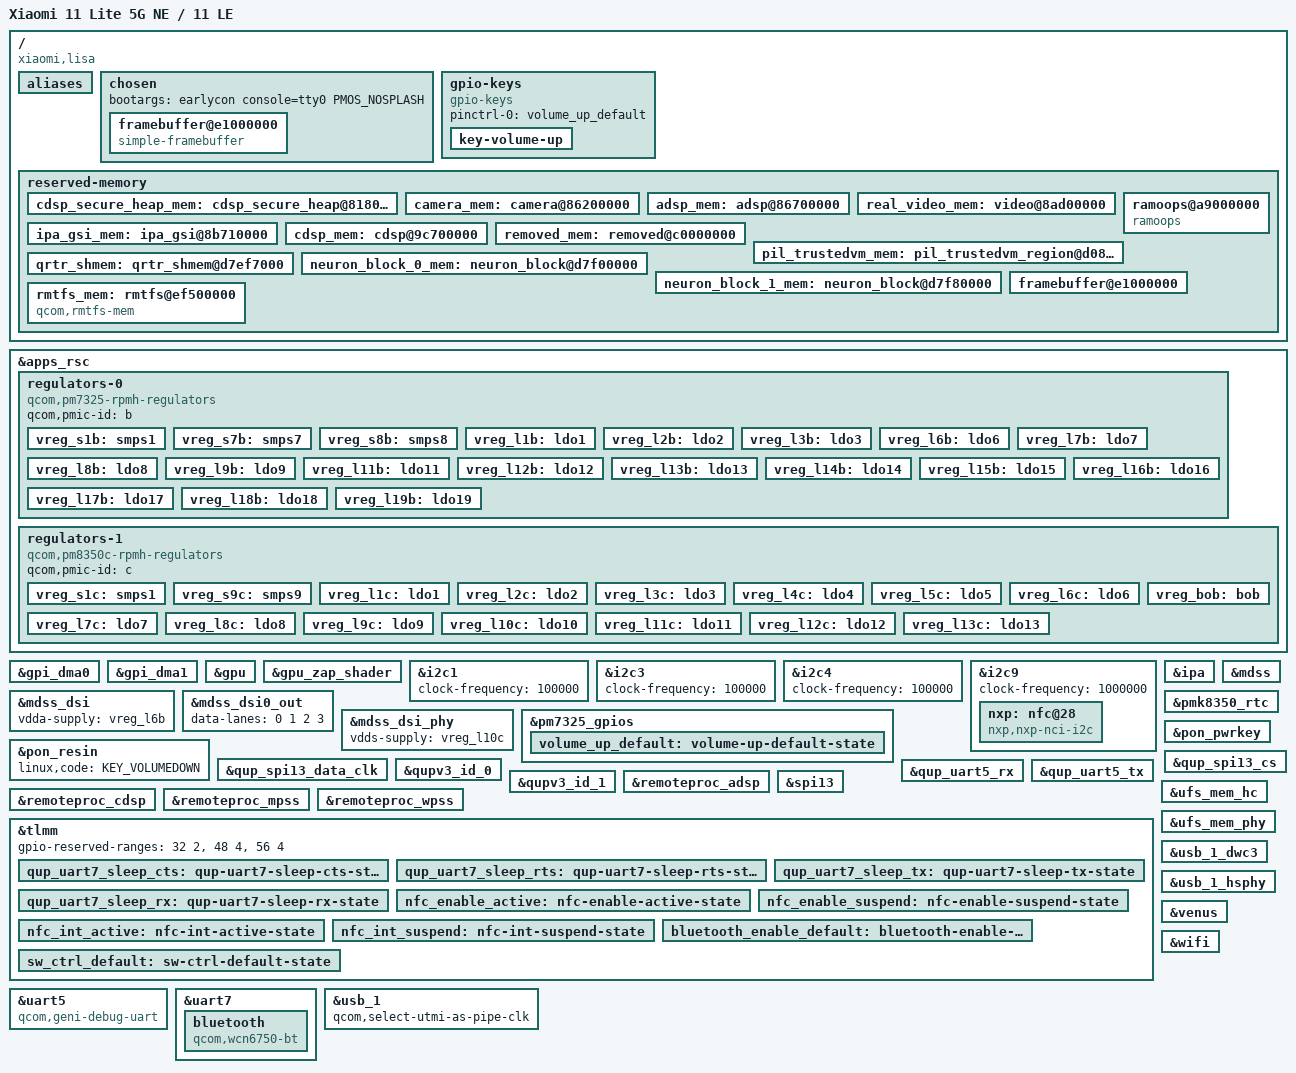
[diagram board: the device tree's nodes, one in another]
// SPDX-License-Identifier: BSD-3-Clause
/*
 * Copyright (c) 2024, Jens Reidel <adrian@travitia.xyz>
 */

/dts-v1/;

#include <dt-bindings/gpio/gpio.h>
#include <dt-bindings/regulator/qcom,rpmh-regulator.h>
#include <dt-bindings/leds/common.h>

#include <dt-bindings/pinctrl/qcom,pmic-gpio.h>
#include "sm7325.dtsi"
#include "pm7325.dtsi"
#include "pm8350b.dtsi" /* PM7325B */
#include "pm8350c.dtsi" /* PM7350C */
#include "pmk8350.dtsi" /* PMK7325 */
#include "pmr735a.dtsi"
/*
 * pmk8350 @ 0
 * pm7325  @ 1
 * pm8350c @ 2
 * pm8350b @ 3
 * pmr735a @ 4
 */

/* The following reserved memory regions have different addresses or sizes */
/delete-node/ &adsp_mem;
/delete-node/ &cdsp_mem;
/delete-node/ &rmtfs_mem;

/ {
	model = "Xiaomi 11 Lite 5G NE / 11 LE";
	compatible = "xiaomi,lisa", "qcom,sm7325";
	qcom,msm-id = <475 0x10000>;
	qcom,board-id = <0x1000b 0x00>;
	chassis-type = "handset";

	aliases {
		serial0 = &uart5;
		serial1 = &uart7;
	};

	chosen {
		#address-cells = <2>;
		#size-cells = <2>;
		ranges;

		//stdout-path = "serial0:115200n8";
		bootargs = "earlycon console=tty0 PMOS_NOSPLASH";

		framebuffer@e1000000 {
			compatible = "simple-framebuffer";
			reg = <0x0 0xe1000000 0x0 (1080 * 2400 * 4)>;
			width = <1080>;
			height = <2400>;
			stride = <(1080 * 4)>;
			format = "a8r8g8b8";
		};
	};

	gpio-keys {
		compatible = "gpio-keys";

		pinctrl-0 = <&volume_up_default>;
		pinctrl-names = "default";

		key-volume-up {
			label = "Volume up";
			gpios = <&pm7325_gpios 6 GPIO_ACTIVE_LOW>;
			linux,code = <KEY_VOLUMEUP>;
		};
	};

	/*
	pmic-glink {
		compatible = "qcom,sm7325-pmic-glink",
			     "qcom,pmic-glink";

		#address-cells = <1>;
		#size-cells = <0>;

		connector@0 {
			compatible = "usb-c-connector";
			reg = <0>;
			power-role = "dual";
			data-role = "dual";

			ports {
				#address-cells = <1>;
				#size-cells = <0>;

				port@0 {
					reg = <0>;

					pmic_glink_hs_in: endpoint {
						remote-endpoint = <&usb_1_dwc3_hs>;
					};
				};

				port@1 {
					reg = <1>;

					pmic_glink_sbu: endpoint {
						remote-endpoint = <&fsa4480_sbu_mux>;
					};
				};
			};
		};
	};
	*/

	reserved-memory {
		#address-cells = <2>;
		#size-cells = <2>;
		ranges;

		cdsp_secure_heap_mem: cdsp_secure_heap@81800000 {
			reg = <0x0 0x81800000 0x0 0x1e00000>;
			no-map;
		};

		camera_mem: camera@86200000 {
			reg = <0x0 0x86200000 0x0 0x500000>;
			no-map;
		};

		adsp_mem: adsp@86700000 {
			reg = <0x0 0x86700000 0x0 0x4000000>;
			no-map;
		};

		/* Mainline video_mem is downstream cvp_mem */
		real_video_mem: video@8ad00000 {
			reg = <0x0 0x8ad00000 0x0 0x500000>;
			no-map;
		};

		ipa_gsi_mem: ipa_gsi@8b710000 {
			reg = <0x0 0x8b710000 0x0 0xa000>;
			no-map;
		};

		cdsp_mem: cdsp@9c700000 {
			reg = <0x0 0x9c700000 0x0 0x1e00000>;
			no-map;
		};

		ramoops@a9000000 {
			compatible = "ramoops";
			reg = <0x0 0xa9000000 0x0 0x200000>;
			pmsg-size = <0x200000>;
			mem-type = <0x02>;
		};

		removed_mem: removed@c0000000 {
			reg = <0x0 0xc0000000 0x0 0x5100000>;
			no-map;
		};

		pil_trustedvm_mem: pil_trustedvm_region@d0800000 {
			reg = <0x0 0xd0800000 0x0 0x76f7000>;
			no-map;
		};

		qrtr_shmem: qrtr_shmem@d7ef7000 {
			reg = <0x0 0xd7ef7000 0x0 0x9000>;
			no-map;
		};

		neuron_block_0_mem: neuron_block@d7f00000 {
			reg = <0x0 0xd7f00000 0x0 0x80000>;
			no-map;
		};

		neuron_block_1_mem: neuron_block@d7f80000 {
			reg = <0x0 0xd7f80000 0x0 0x80000>;
			no-map;
		};

		framebuffer@e1000000 {
			reg = <0x0 0xe1000000 0x0 (1080 * 2400 * 4)>;
			no-map;
		};

		rmtfs_mem: rmtfs@ef500000 {
			compatible = "qcom,rmtfs-mem";
			reg = <0x0 0xef500000 0x0 0x280000>;
			no-map;

			qcom,client-id = <1>;
			qcom,vmid = <QCOM_SCM_VMID_MSS_MSA>,
				    <QCOM_SCM_VMID_NAV>;
		};
	};

	/*
	thermal-zones {
		camera-thermal {
			polling-delay-passive = <0>;
			polling-delay = <0>;
			thermal-sensors = <&pmk8350_adc_tm 2>;

			trips {
				active-config0 {
					temperature = <125000>;
					hysteresis = <1000>;
					type = "passive";
				};
			};
		};

		chg-skin-thermal {
			polling-delay-passive = <0>;
			polling-delay = <0>;
			thermal-sensors = <&pmk8350_adc_tm 6>;

			trips {
				active-config0 {
					temperature = <125000>;
					hysteresis = <1000>;
					type = "passive";
				};
			};
		};

		conn-thermal {
			polling-delay-passive = <0>;
			polling-delay = <0>;
			thermal-sensors = <&pmk8350_adc_tm 5>;

			trips {
				active-config0 {
					temperature = <125000>;
					hysteresis = <1000>;
					type = "passive";
				};
			};
		};

		quiet-thermal {
			polling-delay-passive = <0>;
			polling-delay = <0>;
			thermal-sensors = <&pmk8350_adc_tm 1>;

			trips {
				active-config0 {
					temperature = <125000>;
					hysteresis = <1000>;
					type = "passive";
				};
			};
		};

		rear-cam-thermal {
			polling-delay-passive = <0>;
			polling-delay = <0>;
			thermal-sensors = <&pmk8350_adc_tm 4>;

			trips {
				active-config0 {
					temperature = <125000>;
					hysteresis = <1000>;
					type = "passive";
				};
			};
		};

		sdm-skin-thermal {
			polling-delay-passive = <0>;
			polling-delay = <0>;
			thermal-sensors = <&pmk8350_adc_tm 3>;

			trips {
				active-config0 {
					temperature = <125000>;
					hysteresis = <1000>;
					type = "passive";
				};
			};
		};

		xo-thermal {
			polling-delay-passive = <0>;
			polling-delay = <0>;
			thermal-sensors = <&pmk8350_adc_tm 0>;

			trips {
				active-config0 {
					temperature = <125000>;
					hysteresis = <1000>;
					type = "passive";
				};
			};
		};
	};
	*/
};

&apps_rsc {
	regulators-0 {
		compatible = "qcom,pm7325-rpmh-regulators";
		qcom,pmic-id = "b";

		vreg_s1b: smps1 {
			regulator-min-microvolt = <1840000>;
			regulator-max-microvolt = <2040000>;
		};

		vreg_s7b: smps7 {
			regulator-min-microvolt = <535000>;
			regulator-max-microvolt = <1120000>;
		};

		vreg_s8b: smps8 {
			regulator-min-microvolt = <1200000>;
			regulator-max-microvolt = <1500000>;
			regulator-initial-mode = <RPMH_REGULATOR_MODE_RET>;
		};

		vreg_l1b: ldo1 {
			regulator-min-microvolt = <825000>;
			regulator-max-microvolt = <925000>;
			regulator-initial-mode = <RPMH_REGULATOR_MODE_HPM>;
		};

		vreg_l2b: ldo2 {
			regulator-min-microvolt = <2700000>;
			regulator-max-microvolt = <3544000>;
			regulator-initial-mode = <RPMH_REGULATOR_MODE_HPM>;
		};

		vreg_l3b: ldo3 {
			regulator-min-microvolt = <312000>;
			regulator-max-microvolt = <910000>;
			regulator-initial-mode = <RPMH_REGULATOR_MODE_HPM>;
		};

		vreg_l6b: ldo6 {
			regulator-min-microvolt = <1140000>;
			regulator-max-microvolt = <1260000>;
			regulator-initial-mode = <RPMH_REGULATOR_MODE_HPM>;
			regulator-allow-set-load;
			regulator-allowed-modes = <RPMH_REGULATOR_MODE_LPM
						   RPMH_REGULATOR_MODE_HPM>;
		};

		vreg_l7b: ldo7 {
			regulator-min-microvolt = <2400000>;
			regulator-max-microvolt = <3544000>;
			regulator-initial-mode = <RPMH_REGULATOR_MODE_HPM>;
			regulator-allow-set-load;
			regulator-allowed-modes = <RPMH_REGULATOR_MODE_LPM
						   RPMH_REGULATOR_MODE_HPM>;
		};

		vreg_l8b: ldo8 {
			regulator-min-microvolt = <870000>;
			regulator-max-microvolt = <970000>;
			regulator-initial-mode = <RPMH_REGULATOR_MODE_HPM>;
		};

		vreg_l9b: ldo9 {
			regulator-min-microvolt = <1200000>;
			regulator-max-microvolt = <1304000>;
			regulator-initial-mode = <RPMH_REGULATOR_MODE_HPM>;
			regulator-allow-set-load;
			regulator-allowed-modes = <RPMH_REGULATOR_MODE_LPM
						   RPMH_REGULATOR_MODE_HPM>;
		};

		vreg_l11b: ldo11 {
			regulator-min-microvolt = <1504000>;
			regulator-max-microvolt = <2000000>;
			regulator-initial-mode = <RPMH_REGULATOR_MODE_HPM>;
		};

		vreg_l12b: ldo12 {
			regulator-min-microvolt = <751000>;
			regulator-max-microvolt = <824000>;
			regulator-initial-mode = <RPMH_REGULATOR_MODE_HPM>;
		};

		vreg_l13b: ldo13 {
			regulator-min-microvolt = <530000>;
			regulator-max-microvolt = <824000>;
			regulator-initial-mode = <RPMH_REGULATOR_MODE_HPM>;
		};

		vreg_l14b: ldo14 {
			regulator-min-microvolt = <1080000>;
			regulator-max-microvolt = <1304000>;
			regulator-initial-mode = <RPMH_REGULATOR_MODE_HPM>;
		};

		vreg_l15b: ldo15 {
			regulator-min-microvolt = <765000>;
			regulator-max-microvolt = <1020000>;
			regulator-initial-mode = <RPMH_REGULATOR_MODE_HPM>;
		};

		vreg_l16b: ldo16 {
			regulator-min-microvolt = <1100000>;
			regulator-max-microvolt = <1300000>;
			regulator-initial-mode = <RPMH_REGULATOR_MODE_HPM>;
		};

		vreg_l17b: ldo17 {
			regulator-min-microvolt = <1700000>;
			regulator-max-microvolt = <1900000>;
			regulator-initial-mode = <RPMH_REGULATOR_MODE_HPM>;
		};

		vreg_l18b: ldo18 {
			regulator-min-microvolt = <1800000>;
			regulator-max-microvolt = <2000000>;
			regulator-initial-mode = <RPMH_REGULATOR_MODE_HPM>;
		};

		vreg_l19b: ldo19 {
			regulator-min-microvolt = <1800000>;
			regulator-max-microvolt = <2000000>;
			regulator-initial-mode = <RPMH_REGULATOR_MODE_HPM>;
		};
	};

	regulators-1 {
		compatible = "qcom,pm8350c-rpmh-regulators";
		qcom,pmic-id = "c";

		vreg_s1c: smps1 {
			regulator-min-microvolt = <2190000>;
			regulator-max-microvolt = <2210000>;
		};

		vreg_s9c: smps9 {
			regulator-min-microvolt = <1010000>;
			regulator-max-microvolt = <1170000>;
		};

		vreg_l1c: ldo1 {
			regulator-min-microvolt = <1800000>;
			regulator-max-microvolt = <1980000>;
			regulator-initial-mode = <RPMH_REGULATOR_MODE_HPM>;
		};

		vreg_l2c: ldo2 {
			regulator-min-microvolt = <1620000>;
			regulator-max-microvolt = <1980000>;
			regulator-initial-mode = <RPMH_REGULATOR_MODE_HPM>;
		};

		vreg_l3c: ldo3 {
			regulator-min-microvolt = <3300000>;
			regulator-max-microvolt = <3300000>;
			regulator-initial-mode = <RPMH_REGULATOR_MODE_HPM>;
			regulator-always-on;
		};

		vreg_l4c: ldo4 {
			regulator-min-microvolt = <1620000>;
			regulator-max-microvolt = <3300000>;
			regulator-initial-mode = <RPMH_REGULATOR_MODE_HPM>;
		};

		vreg_l5c: ldo5 {
			regulator-min-microvolt = <1620000>;
			regulator-max-microvolt = <3300000>;
			regulator-initial-mode = <RPMH_REGULATOR_MODE_HPM>;
		};

		vreg_l6c: ldo6 {
			regulator-min-microvolt = <1650000>;
			regulator-max-microvolt = <3544000>;
			regulator-initial-mode = <RPMH_REGULATOR_MODE_HPM>;
		};

		vreg_l7c: ldo7 {
			regulator-min-microvolt = <3000000>;
			regulator-max-microvolt = <3544000>;
			regulator-initial-mode = <RPMH_REGULATOR_MODE_HPM>;
		};

		vreg_l8c: ldo8 {
			regulator-min-microvolt = <1620000>;
			regulator-max-microvolt = <2000000>;
			regulator-initial-mode = <RPMH_REGULATOR_MODE_HPM>;
			regulator-always-on;
		};

		vreg_l9c: ldo9 {
			regulator-min-microvolt = <2700000>;
			regulator-max-microvolt = <3544000>;
			regulator-initial-mode = <RPMH_REGULATOR_MODE_HPM>;
		};

		vreg_l10c: ldo10 {
			regulator-min-microvolt = <720000>;
			regulator-max-microvolt = <1050000>;
			regulator-initial-mode = <RPMH_REGULATOR_MODE_HPM>;
			regulator-allow-set-load;
			regulator-allowed-modes = <RPMH_REGULATOR_MODE_LPM
						   RPMH_REGULATOR_MODE_HPM>;
		};

		vreg_l11c: ldo11 {
			regulator-min-microvolt = <2800000>;
			regulator-max-microvolt = <3544000>;
			regulator-initial-mode = <RPMH_REGULATOR_MODE_HPM>;
		};

		vreg_l12c: ldo12 {
			regulator-min-microvolt = <1650000>;
			regulator-max-microvolt = <2000000>;
			regulator-initial-mode = <RPMH_REGULATOR_MODE_HPM>;
		};

		vreg_l13c: ldo13 {
			regulator-min-microvolt = <2700000>;
			regulator-max-microvolt = <3544000>;
			regulator-initial-mode = <RPMH_REGULATOR_MODE_HPM>;
		};

		vreg_bob: bob {
			regulator-min-microvolt = <3008000>;
			regulator-max-microvolt = <3960000>;
			regulator-initial-mode = <RPMH_REGULATOR_MODE_AUTO>;
		};
	};
};

/*
&cci0 {
	status = "okay";
};

&cci1 {
	status = "okay";
};
*/

&gpi_dma0 {
	status = "okay";
};

&gpi_dma1 {
	status = "okay";
};

&gpu {
	status = "okay";
};

&gpu_zap_shader {
	firmware-name = "qcom/sm7325/xiaomi/lisa/a660_zap.mbn";
};

&i2c1 {
	clock-frequency = <100000>;
	status = "okay";

	/*
	 * Downstream DTS has 4 pm8008X pmics, but i2cdetect
	 * doesnt see any devices at these addresses
	 *
	 * #include "pm8008.dtsi"
	 *
         * pm8008i qcom,i2c-pmic @ 8
	 * pm8008i qcom,i2c-pmic @ 9
	 * pm8008j qcom,i2c-pmic @ c
	 * pm8008j qcom,i2c-pmic @ d
	 *
	 */

	/* awinic,aw210xx_led @ 20 */

	/* TODO: It has this but supply?
	fsa4480: switcher@42 {
		compatible = "fcs,fsa4480";
		reg = <0x42>;

		vcc-supply = <&vreg_bob>;

		mode-switch;
		orientation-switch;

		port {
			fsa4480_sbu_mux: endpoint {
				remote-endpoint = <&pmic_glink_sbu>;
			};
		};
	};
	*/

	/*
	 * I guess this is also not used:
	 *
	 * nq rtc6226 @ 64
	 */
};

&i2c3 {
	clock-frequency = <100000>;
	status = "okay";

	/* tfa,tfa98xx @ 34 */
	/* tfa,tfa98xx @ 35 */
};

&i2c4 {
	clock-frequency = <100000>;
	status = "okay";

	/* awinic,aw8624_haptic @ 5a */
};

&i2c9 {
	clock-frequency = <1000000>;
	status = "okay";

	nxp: nfc@28 {
		compatible = "nxp,nxp-nci-i2c";
		reg = <0x28>;

		interrupt-parent = <&tlmm>;
		interrupts = <41 IRQ_TYPE_NONE>;

		enable-gpios = <&tlmm 38 GPIO_ACTIVE_HIGH>;
		firmware-gpios = <&tlmm 40 GPIO_ACTIVE_HIGH>;

		pinctrl-names = "default", "sleep";
		pinctrl-0 = <&nfc_enable_active>, <&nfc_int_active>;
		pinctrl-1 = <&nfc_enable_suspend>, <&nfc_int_suspend>;
	};
};

&ipa {
	qcom,gsi-loader = "self";
	memory-region = <&ipa_fw_mem>;
	firmware-name = "qcom/sm7325/xiaomi/lisa/ipa_fws.mbn";
	status = "okay";
};

&mdss {
	status = "okay";
};

&mdss_dsi {
	vdda-supply = <&vreg_l6b>;
	status = "okay";

	/*
	drm_panel: panel@0 {
		compatible = "mdss,rm692e5-visionox-amoled-120hz";
		reg = <0>;

		reset-gpios = <&tlmm 44 GPIO_ACTIVE_LOW>;

		vdd-supply = <&vreg_l13c>;
		vddio-supply = <&vreg_l12c>;

		pinctrl-0 = <&sde_dsi_active &sde_te_active_sleep>;
		pinctrl-1 = <&sde_dsi_sleep &sde_te_active_sleep>;
		pinctrl-names = "default", "sleep";

		port {
			panel_in: endpoint {
				remote-endpoint = <&mdss_dsi0_out>;
			};
		};
	};
	*/
};

&mdss_dsi0_out {
	data-lanes = <0 1 2 3>;
	//remote-endpoint = <&panel_in>;
};

&mdss_dsi_phy {
	vdds-supply = <&vreg_l10c>;
	status = "okay";
};

&pm7325_gpios {
	volume_up_default: volume-up-default-state {
		pins = "gpio6";
		function = PMIC_GPIO_FUNC_NORMAL;
		power-source = <1>;
		bias-pull-up;
		input-enable;
	};
};

/*
&pm8350c_flash {
	status = "okay";

	led-0 {
		function = LED_FUNCTION_FLASH;
		color = <LED_COLOR_ID_WHITE>;
		led-sources = <1>, <4>;
		led-max-microamp = <500000>;
		flash-max-microamp = <1500000>;
		flash-max-timeout-us = <1280000>;
	};
};
*/

&pmk8350_rtc {
	status = "okay";
};

&pon_pwrkey {
	status = "okay";
};

&pon_resin {
	linux,code = <KEY_VOLUMEDOWN>;
	status = "okay";
};

&qup_spi13_cs {
	drive-strength = <6>;
	bias-disable;
};

&qup_spi13_data_clk {
	drive-strength = <6>;
	bias-disable;
};

&qup_uart5_rx {
	drive-strength = <2>;
	bias-disable;
};

&qup_uart5_tx {
	drive-strength = <2>;
	bias-disable;
};

&qupv3_id_0 {
	status = "okay";
};

&qupv3_id_1 {
	status = "okay";
};

&remoteproc_adsp {
	firmware-name = "qcom/sm7325/xiaomi/lisa/adsp.mbn";
	status = "okay";
};

&remoteproc_cdsp {
	firmware-name = "qcom/sm7325/xiaomi/lisa/cdsp.mbn";
	status = "okay";
};

&remoteproc_mpss {
	firmware-name = "qcom/sm7325/xiaomi/lisa/modem.mbn";
	status = "okay";
};

&remoteproc_wpss {
	firmware-name = "qcom/sm7325/xiaomi/lisa/wpss.mbn";
	status = "okay";
};

&spi13 {
	status = "okay";

	/* xiaomi,k9-spi @ 0 */
};


&tlmm {
	/*
	 * 32-33: SMB1394 (SPMI)
	 * 56-59: fingerprint reader (SPI)
	 */
	gpio-reserved-ranges = <32 2>, <48 4>, <56 4>;

	qup_uart7_sleep_cts: qup-uart7-sleep-cts-state {
		pins = "gpio28";
		function = "gpio";
		/*
		 * Configure a bias-bus-hold on CTS to lower power
		 * usage when Bluetooth is turned off. Bus hold will
		 * maintain a low power state regardless of whether
		 * the Bluetooth module drives the pin in either
		 * direction or leaves the pin fully unpowered.
		 */
		bias-bus-hold;
	};

	qup_uart7_sleep_rts: qup-uart7-sleep-rts-state {
		pins = "gpio29";
		function = "gpio";
		/*
		 * Configure pull-down on RTS. As RTS is active low
		 * signal, pull it low to indicate the BT SoC that it
		 * can wakeup the system anytime from suspend state by
		 * pulling RX low (by sending wakeup bytes).
		 */
		bias-pull-down;
	};

	qup_uart7_sleep_tx: qup-uart7-sleep-tx-state {
		pins = "gpio30";
		function = "gpio";
		/*
		 * Configure pull-up on TX when it isn't actively driven
		 * to prevent BT SoC from receiving garbage during sleep.
		 */
		bias-pull-up;
	};

	qup_uart7_sleep_rx: qup-uart7-sleep-rx-state {
		pins = "gpio31";
		function = "gpio";
		/*
		 * Configure a pull-up on RX. This is needed to avoid
		 * garbage data when the TX pin of the Bluetooth module
		 * is floating which may cause spurious wakeups.
		 */
		bias-pull-up;
	};

	nfc_enable_active: nfc-enable-active-state {
		pins = "gpio38", "gpio40", "gpio39";
		function = "gpio";
		drive-strength = <2>;
		bias-disable;
	};

	nfc_enable_suspend: nfc-enable-suspend-state {
		pins = "gpio38", "gpio40", "gpio39";
		function = "gpio";
		drive-strength = <2>;
		bias-disable;
	};

	nfc_int_active: nfc-int-active-state {
		pins = "gpio41";
		function = "gpio";
		drive-strength = <2>;
		bias-pull-down;
	};

	nfc_int_suspend: nfc-int-suspend-state {
		pins = "gpio41";
		function = "gpio";
		drive-strength = <2>;
		bias-pull-down;
	};

	bluetooth_enable_default: bluetooth-enable-default-state {
		pins = "gpio85";
		function = "gpio";
		output-low;
		bias-disable;
	};

	sw_ctrl_default: sw-ctrl-default-state {
		pins = "gpio86";
		function = "gpio";
		bias-pull-down;
	};
};

&uart5 {
	compatible = "qcom,geni-debug-uart";
	status = "okay";
};

&uart7 {
	/delete-property/interrupts;
	interrupts-extended = <&intc GIC_SPI 608 IRQ_TYPE_LEVEL_HIGH>,
			      <&tlmm 31 IRQ_TYPE_EDGE_FALLING>;

	pinctrl-1 = <&qup_uart7_sleep_cts>,
		    <&qup_uart7_sleep_rts>,
		    <&qup_uart7_sleep_tx>,
		    <&qup_uart7_sleep_rx>;
	pinctrl-names = "default", "sleep";

	status = "okay";

	bluetooth: bluetooth {
		compatible = "qcom,wcn6750-bt";

		pinctrl-0 = <&bluetooth_enable_default>, <&sw_ctrl_default>;
		pinctrl-names = "default";

		enable-gpios = <&tlmm 85 GPIO_ACTIVE_HIGH>;
		swctrl-gpios = <&tlmm 86 GPIO_ACTIVE_HIGH>;

		vddio-supply = <&vreg_l19b>;
		vddaon-supply = <&vreg_s7b>;
		vddbtcxmx-supply = <&vreg_s7b>;
		vddrfacmn-supply = <&vreg_s7b>;
		vddrfa0p8-supply = <&vreg_s7b>;
		vddrfa1p7-supply = <&vreg_s1b>;
		vddrfa1p2-supply = <&vreg_s8b>;
		vddrfa2p2-supply = <&vreg_s1c>;
		vddasd-supply = <&vreg_l11c>;

		max-speed = <3200000>;
	};
};

&ufs_mem_hc {
	reset-gpios = <&tlmm 175 GPIO_ACTIVE_LOW>;

	vcc-supply = <&vreg_l7b>;
	vcc-max-microamp = <800000>;
	/*
	 * Technically l9b enables an eLDO (supplied by s1b) which then powers
	 * VCCQ2 of the UFS.
	 */
	vccq-supply = <&vreg_l9b>;
	vccq-max-microamp = <900000>;

	status = "okay";
};

&ufs_mem_phy {
	vdda-phy-supply = <&vreg_l10c>;
	vdda-pll-supply = <&vreg_l6b>;
	status = "okay";
};

&usb_1 {
	/* USB 2.0 only */
	qcom,select-utmi-as-pipe-clk;
	status = "okay";
};

&usb_1_dwc3 {
	dr_mode = "peripheral";
	//usb-role-switch;
	maximum-speed = "high-speed";
	/* Remove USB3 phy */
	phys = <&usb_1_hsphy>;
	phy-names = "usb2-phy";
};

/*
&usb_1_dwc3_hs {
	remote-endpoint = <&pmic_glink_hs_in>;
};
*/

&usb_1_hsphy {
	vdda-pll-supply = <&vreg_l10c>;
	vdda18-supply = <&vreg_l1c>;
	vdda33-supply = <&vreg_l2b>;
	status = "okay";
};

&venus {
	firmware-name = "qcom/sm7325/xiaomi/lisa/venus.mbn";
	status = "okay";
};

&wifi {
	status = "okay";
};
